# NPCX498S register map
File version: 1.0
Registers are 8-bit, read-write, reset 0x0 unless marked. A register's access mark holds for its fields unless they carry their own. Offsets are from the block's base; [hi:lo] are bit positions; {n}, {i} and the like mark numbered series.

## ADC_IREF
Base 0x400D1000
Same registers: ADC_EREF 0x400D5000
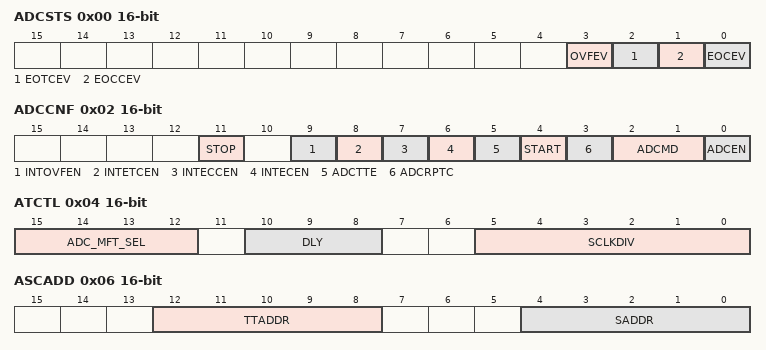
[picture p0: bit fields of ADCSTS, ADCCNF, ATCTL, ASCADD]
0x00 ADCSTS 16-bit — ADC Status Register (ADCSTS)
  [3] OVFEV — Data Overflow Event
  [2] EOTCEV — End Of Timer-Triggered Conversion Event
  [1] EOCCEV — End Of Conversion Cycle Event
  [0] EOCEV — End Of Conversion Event
0x02 ADCCNF 16-bit (reset mask 0xFF) — ADC Configuration Register (ADCCNF)
  [11] STOP — ADC Stop Conversion
  [9] INTOVFEN — Interrupt from Data Overflow Event Enable
  [8] INTETCEN — Interrupt from End Of Timer-Triggered Conversion Event Enable
  [7] INTECCEN — Interrupt from End Of Cyclic-Conversion Event Enable
  [6] INTECEN — Interrupt from End Of Conversion Event Enable
  [5] ADCTTE — ADC Timer-Triggered Conversion Enable
  [4] START — ADC Start Conversion
  [3] ADCRPTC — ADC Repetitive Mode
  [2:1] ADCMD — ADC Conversion Mode
  [0] ADCEN — ADC Module Enable
0x04 ATCTL 16-bit (reset mask 0xFF) — ADC Timing Control Register (ATCTL)
  [15:12] ADC_MFT_SEL — ADC MFT Select
  [10:8] DLY — Channel Delay
  [5:0] SCLKDIV — Basic Clock Division Factor
0x06 ASCADD 16-bit (reset mask 0xFF) — ADC Single Channel Address Register (ASCADD)
  [12:8] TTADDR — Timer-Triggered Address
  [4:0] SADDR — Software-Triggered Address
0x08 ADCCS1 16-bit (reset mask 0xFF) — ADC Scan Channels Select 1 Register (ADCCS1)
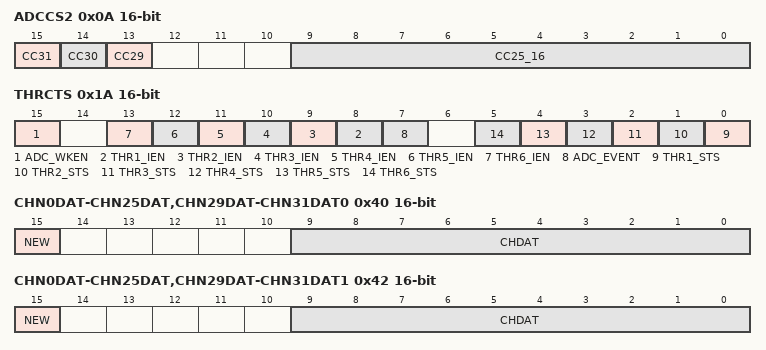
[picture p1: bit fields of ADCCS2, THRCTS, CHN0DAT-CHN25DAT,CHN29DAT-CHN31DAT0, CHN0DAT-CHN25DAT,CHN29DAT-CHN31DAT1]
0x0A ADCCS2 16-bit (reset mask 0xFF) — ADC Scan Channels Select 2 Register (ADCCS2)
  [15] CC31 — Convert Channel 31
  [14] CC30 — Convert Channel 30
  [13] CC29 — Convert Channel 29
  [9:0] CC25_16 — Convert Channel n
0x1A THRCTS 16-bit (reset mask 0xFF) — Threshold Status Register (THRCTS)
  [15] ADC_WKEN — ADC Wake-Up Enable
  [n+7] THR{n}_IEN (n=1..6) — Threshold {n} Interrupt Enable
  [7] ADC_EVENT — ADC Event Status
  [n-1] THR{n}_STS (n=1..6) — Threshold {n} Status
0x40 CHN0DAT-CHN25DAT,CHN29DAT-CHN31DAT0 16-bit (reset mask 0xFF) — Channel n Data Buffer Register (CHNnDAT{, n is 0-25,29-31)})
  [15] NEW — New Conversion Result
  [9:0] CHDAT — Channel Data
0x42 CHN0DAT-CHN25DAT,CHN29DAT-CHN31DAT1 16-bit (reset mask 0xFF) — Channel n Data Buffer Register (CHNnDAT{, n is 0-25,29-31)})
  [15] NEW — New Conversion Result
  [9:0] CHDAT — Channel Data
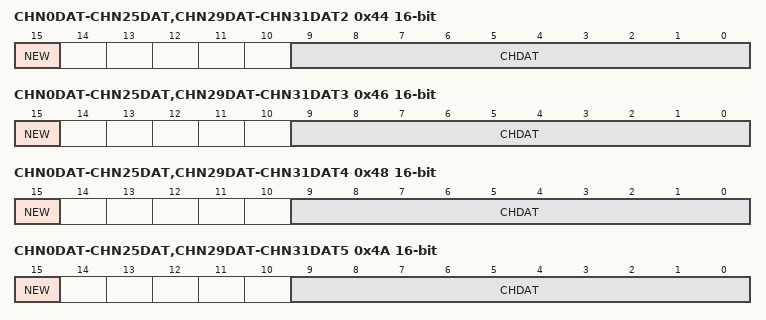
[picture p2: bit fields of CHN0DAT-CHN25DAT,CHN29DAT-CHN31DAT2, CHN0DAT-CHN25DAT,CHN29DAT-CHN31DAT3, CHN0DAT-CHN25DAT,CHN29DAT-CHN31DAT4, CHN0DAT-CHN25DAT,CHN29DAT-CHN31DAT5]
0x44 CHN0DAT-CHN25DAT,CHN29DAT-CHN31DAT2 16-bit (reset mask 0xFF) — Channel n Data Buffer Register (CHNnDAT{, n is 0-25,29-31)})
  [15] NEW — New Conversion Result
  [9:0] CHDAT — Channel Data
0x46 CHN0DAT-CHN25DAT,CHN29DAT-CHN31DAT3 16-bit (reset mask 0xFF) — Channel n Data Buffer Register (CHNnDAT{, n is 0-25,29-31)})
  [15] NEW — New Conversion Result
  [9:0] CHDAT — Channel Data
0x48 CHN0DAT-CHN25DAT,CHN29DAT-CHN31DAT4 16-bit (reset mask 0xFF) — Channel n Data Buffer Register (CHNnDAT{, n is 0-25,29-31)})
  [15] NEW — New Conversion Result
  [9:0] CHDAT — Channel Data
0x4A CHN0DAT-CHN25DAT,CHN29DAT-CHN31DAT5 16-bit (reset mask 0xFF) — Channel n Data Buffer Register (CHNnDAT{, n is 0-25,29-31)})
  [15] NEW — New Conversion Result
  [9:0] CHDAT — Channel Data
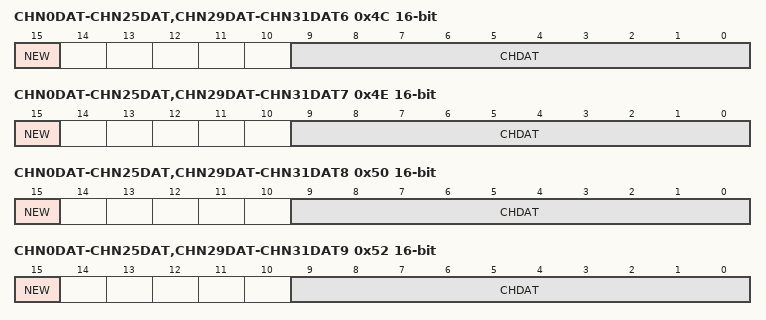
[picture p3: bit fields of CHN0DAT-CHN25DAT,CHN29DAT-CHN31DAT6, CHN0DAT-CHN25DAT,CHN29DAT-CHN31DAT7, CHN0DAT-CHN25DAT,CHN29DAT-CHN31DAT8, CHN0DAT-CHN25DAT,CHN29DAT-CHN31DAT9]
0x4C CHN0DAT-CHN25DAT,CHN29DAT-CHN31DAT6 16-bit (reset mask 0xFF) — Channel n Data Buffer Register (CHNnDAT{, n is 0-25,29-31)})
  [15] NEW — New Conversion Result
  [9:0] CHDAT — Channel Data
0x4E CHN0DAT-CHN25DAT,CHN29DAT-CHN31DAT7 16-bit (reset mask 0xFF) — Channel n Data Buffer Register (CHNnDAT{, n is 0-25,29-31)})
  [15] NEW — New Conversion Result
  [9:0] CHDAT — Channel Data
0x50 CHN0DAT-CHN25DAT,CHN29DAT-CHN31DAT8 16-bit (reset mask 0xFF) — Channel n Data Buffer Register (CHNnDAT{, n is 0-25,29-31)})
  [15] NEW — New Conversion Result
  [9:0] CHDAT — Channel Data
0x52 CHN0DAT-CHN25DAT,CHN29DAT-CHN31DAT9 16-bit (reset mask 0xFF) — Channel n Data Buffer Register (CHNnDAT{, n is 0-25,29-31)})
  [15] NEW — New Conversion Result
  [9:0] CHDAT — Channel Data
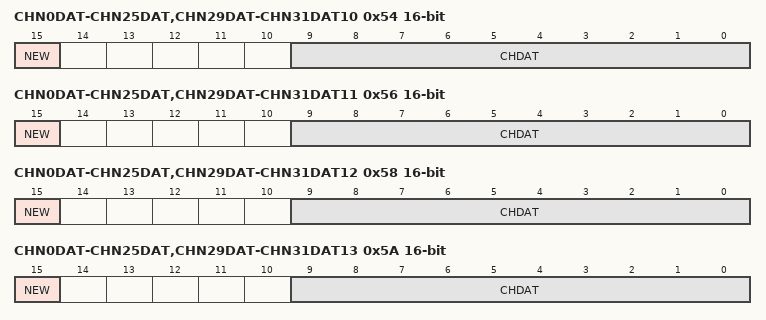
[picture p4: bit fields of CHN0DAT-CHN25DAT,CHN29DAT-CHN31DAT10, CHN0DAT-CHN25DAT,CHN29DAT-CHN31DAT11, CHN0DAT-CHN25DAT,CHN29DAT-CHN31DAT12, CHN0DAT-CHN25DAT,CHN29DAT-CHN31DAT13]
0x54 CHN0DAT-CHN25DAT,CHN29DAT-CHN31DAT10 16-bit (reset mask 0xFF) — Channel n Data Buffer Register (CHNnDAT{, n is 0-25,29-31)})
  [15] NEW — New Conversion Result
  [9:0] CHDAT — Channel Data
0x56 CHN0DAT-CHN25DAT,CHN29DAT-CHN31DAT11 16-bit (reset mask 0xFF) — Channel n Data Buffer Register (CHNnDAT{, n is 0-25,29-31)})
  [15] NEW — New Conversion Result
  [9:0] CHDAT — Channel Data
0x58 CHN0DAT-CHN25DAT,CHN29DAT-CHN31DAT12 16-bit (reset mask 0xFF) — Channel n Data Buffer Register (CHNnDAT{, n is 0-25,29-31)})
  [15] NEW — New Conversion Result
  [9:0] CHDAT — Channel Data
0x5A CHN0DAT-CHN25DAT,CHN29DAT-CHN31DAT13 16-bit (reset mask 0xFF) — Channel n Data Buffer Register (CHNnDAT{, n is 0-25,29-31)})
  [15] NEW — New Conversion Result
  [9:0] CHDAT — Channel Data
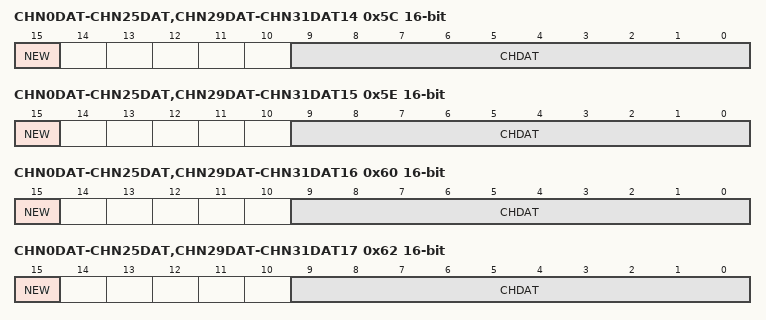
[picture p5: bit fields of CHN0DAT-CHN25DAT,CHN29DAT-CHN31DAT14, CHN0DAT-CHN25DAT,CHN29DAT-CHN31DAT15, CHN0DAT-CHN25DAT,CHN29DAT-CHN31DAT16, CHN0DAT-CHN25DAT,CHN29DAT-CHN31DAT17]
0x5C CHN0DAT-CHN25DAT,CHN29DAT-CHN31DAT14 16-bit (reset mask 0xFF) — Channel n Data Buffer Register (CHNnDAT{, n is 0-25,29-31)})
  [15] NEW — New Conversion Result
  [9:0] CHDAT — Channel Data
0x5E CHN0DAT-CHN25DAT,CHN29DAT-CHN31DAT15 16-bit (reset mask 0xFF) — Channel n Data Buffer Register (CHNnDAT{, n is 0-25,29-31)})
  [15] NEW — New Conversion Result
  [9:0] CHDAT — Channel Data
0x60 CHN0DAT-CHN25DAT,CHN29DAT-CHN31DAT16 16-bit (reset mask 0xFF) — Channel n Data Buffer Register (CHNnDAT{, n is 0-25,29-31)})
  [15] NEW — New Conversion Result
  [9:0] CHDAT — Channel Data
0x62 CHN0DAT-CHN25DAT,CHN29DAT-CHN31DAT17 16-bit (reset mask 0xFF) — Channel n Data Buffer Register (CHNnDAT{, n is 0-25,29-31)})
  [15] NEW — New Conversion Result
  [9:0] CHDAT — Channel Data
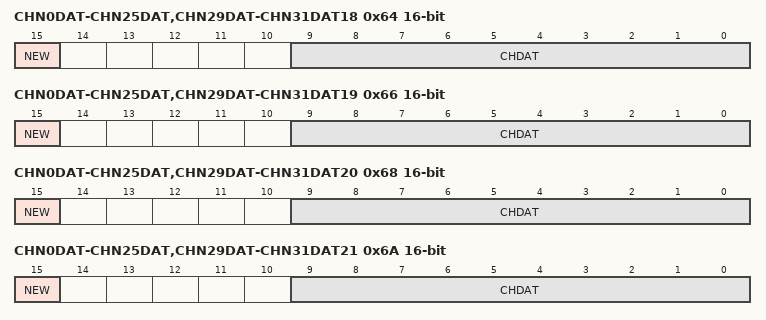
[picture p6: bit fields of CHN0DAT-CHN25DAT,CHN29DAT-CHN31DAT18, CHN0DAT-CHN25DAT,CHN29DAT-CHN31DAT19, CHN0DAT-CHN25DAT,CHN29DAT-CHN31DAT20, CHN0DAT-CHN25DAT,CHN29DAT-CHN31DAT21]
0x64 CHN0DAT-CHN25DAT,CHN29DAT-CHN31DAT18 16-bit (reset mask 0xFF) — Channel n Data Buffer Register (CHNnDAT{, n is 0-25,29-31)})
  [15] NEW — New Conversion Result
  [9:0] CHDAT — Channel Data
0x66 CHN0DAT-CHN25DAT,CHN29DAT-CHN31DAT19 16-bit (reset mask 0xFF) — Channel n Data Buffer Register (CHNnDAT{, n is 0-25,29-31)})
  [15] NEW — New Conversion Result
  [9:0] CHDAT — Channel Data
0x68 CHN0DAT-CHN25DAT,CHN29DAT-CHN31DAT20 16-bit (reset mask 0xFF) — Channel n Data Buffer Register (CHNnDAT{, n is 0-25,29-31)})
  [15] NEW — New Conversion Result
  [9:0] CHDAT — Channel Data
0x6A CHN0DAT-CHN25DAT,CHN29DAT-CHN31DAT21 16-bit (reset mask 0xFF) — Channel n Data Buffer Register (CHNnDAT{, n is 0-25,29-31)})
  [15] NEW — New Conversion Result
  [9:0] CHDAT — Channel Data
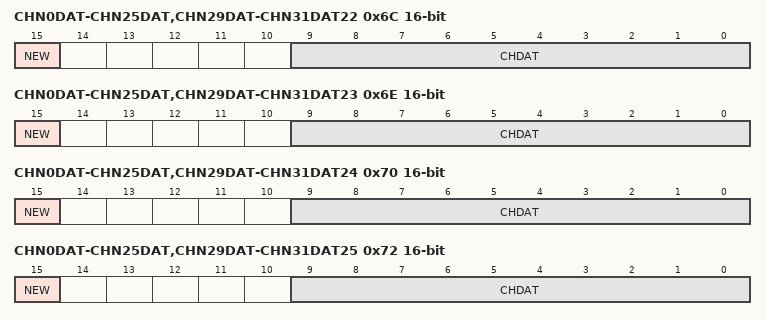
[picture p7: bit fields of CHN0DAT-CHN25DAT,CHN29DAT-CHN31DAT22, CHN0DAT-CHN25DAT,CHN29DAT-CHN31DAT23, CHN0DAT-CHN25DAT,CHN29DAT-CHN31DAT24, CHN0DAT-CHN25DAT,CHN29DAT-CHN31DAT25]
0x6C CHN0DAT-CHN25DAT,CHN29DAT-CHN31DAT22 16-bit (reset mask 0xFF) — Channel n Data Buffer Register (CHNnDAT{, n is 0-25,29-31)})
  [15] NEW — New Conversion Result
  [9:0] CHDAT — Channel Data
0x6E CHN0DAT-CHN25DAT,CHN29DAT-CHN31DAT23 16-bit (reset mask 0xFF) — Channel n Data Buffer Register (CHNnDAT{, n is 0-25,29-31)})
  [15] NEW — New Conversion Result
  [9:0] CHDAT — Channel Data
0x70 CHN0DAT-CHN25DAT,CHN29DAT-CHN31DAT24 16-bit (reset mask 0xFF) — Channel n Data Buffer Register (CHNnDAT{, n is 0-25,29-31)})
  [15] NEW — New Conversion Result
  [9:0] CHDAT — Channel Data
0x72 CHN0DAT-CHN25DAT,CHN29DAT-CHN31DAT25 16-bit (reset mask 0xFF) — Channel n Data Buffer Register (CHNnDAT{, n is 0-25,29-31)})
  [15] NEW — New Conversion Result
  [9:0] CHDAT — Channel Data
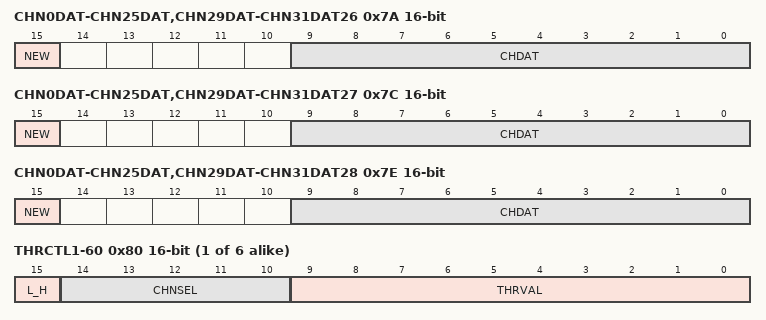
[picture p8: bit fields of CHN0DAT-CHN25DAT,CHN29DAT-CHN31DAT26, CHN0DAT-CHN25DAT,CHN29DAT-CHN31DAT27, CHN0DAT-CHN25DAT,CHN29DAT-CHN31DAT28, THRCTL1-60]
0x7A CHN0DAT-CHN25DAT,CHN29DAT-CHN31DAT26 16-bit (reset mask 0xFF) — Channel n Data Buffer Register (CHNnDAT{, n is 0-25,29-31)})
  [15] NEW — New Conversion Result
  [9:0] CHDAT — Channel Data
0x7C CHN0DAT-CHN25DAT,CHN29DAT-CHN31DAT27 16-bit (reset mask 0xFF) — Channel n Data Buffer Register (CHNnDAT{, n is 0-25,29-31)})
  [15] NEW — New Conversion Result
  [9:0] CHDAT — Channel Data
0x7E CHN0DAT-CHN25DAT,CHN29DAT-CHN31DAT28 16-bit (reset mask 0xFF) — Channel n Data Buffer Register (CHNnDAT{, n is 0-25,29-31)})
  [15] NEW — New Conversion Result
  [9:0] CHDAT — Channel Data
{0x8+2i} THRCTL1-{i} 16-bit (reset mask 0xFF) (i=60..65) — Threshold Control 1-6 Register (THRCTL1-6)
  [15] L_H — Lower or Higher
  [14:10] CHNSEL — Channel Select
  [9:0] THRVAL — Threshold Value
0x90 THEN 16-bit — Threshold Enable Register (THEN)
  [5:0] THEN6_1 — Threshold Enable
